AUTOSAR XML (schema 4-2-2)
package /ComponentTypes
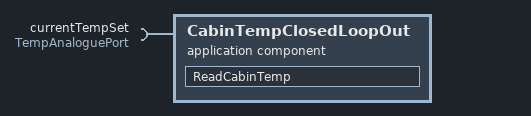
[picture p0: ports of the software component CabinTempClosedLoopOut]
  application sw component type CabinTempClosedLoopOut
    require port currentTempSet: required-interface=TempAnaloguePort
      required-com-specs:
        data-element=tempOut, filter=data-filter-type=ALWAYS, init-value=0
        data-element=tempIn, filter=data-filter-type=ALWAYS, init-value=0
    behavior CabinTempClosedLoopOut_InternalBehavior: data-type-mapping=tempMapSet
      data received event DRT_ReadCabinTemp_currentTempSet_tempIn: start-on-event=ReadCabinTemp, data=currentTempSet.tempIn
      runnable ReadCabinTemp
        data-receive-point-by-arguments:
          access REC_currentTempSet_tempIn: accessed-variable=currentTempSet.tempIn
          access REC_currentTempSet_tempOut: accessed-variable=currentTempSet.tempOut
  swc implementation CabinTempClosedLoopOut_Implementation: behavior=CabinTempClosedLoopOut_InternalBehavior
